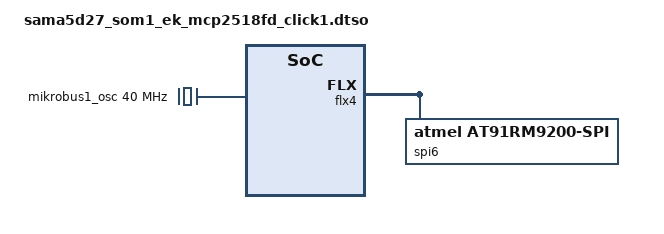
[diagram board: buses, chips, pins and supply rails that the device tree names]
// SPDX-License-Identifier: (GPL-2.0+ OR MIT)
/*
 * Device Tree file for SAMA5D27 SOM1 EK board
 * overlay blob for Mikroe MCP2517FD/18FD/MCP251863 board on Click 1.
 * The blob uses SPI on flx4.
 *
 * Copyright (C) 2022 Microchip Technology Inc. and its subsidiaries
 * Author: Thomas Kopp <thomas.kopp@microchip.com>
 *
 */
/dts-v1/;
/plugin/;

#include "sama5d2-pinfunc.h"
#include "dt-bindings/pinctrl/at91.h"
#include <dt-bindings/mfd/atmel-flexcom.h>

&flx4 {
	atmel,flexcom-mode = <ATMEL_FLEXCOM_MODE_SPI>;
	#address-cells = <1>;
	#size-cells = <1>;
	status = "okay";

	spi6: spi@400{
		compatible = "atmel,at91rm9200-spi";
		reg = <0x400 0x200>;
		#address-cells = <1>;
		#size-cells = <0>;
		clock-names = "spi_clk";
		atmel,fifo-size = <16>;
		pinctrl-names = "default";
		pinctrl-0 = <&pinctrl_mikrobus_spi>;
		status = "okay";

		mcp2518fd: can@1{
			compatible = "microchip,mcp2518fd";
			spi-max-frequency = <20000000>;
			reg = <1>;

			interrupt-parent = <&pioA>;
			interrupts = <PIN_PB0 8>;

			pinctrl-names = "default";
			pinctrl-0 = <&pinctrl_mikrobus1_int  &pinctrl_mikrobus1_spi_cs>;

			clocks = <&mikrobus1_osc>;
		};
	};
};

&{/} {
	mikrobus1_osc: oscillator_1 {
		compatible = "fixed-clock";
		#clock-cells = <0>;
		clock-frequency = <40000000>;
	};
};
